AUTOSAR XML (schema 00044)
package /E40_Platform_System_SystemPackage/Components
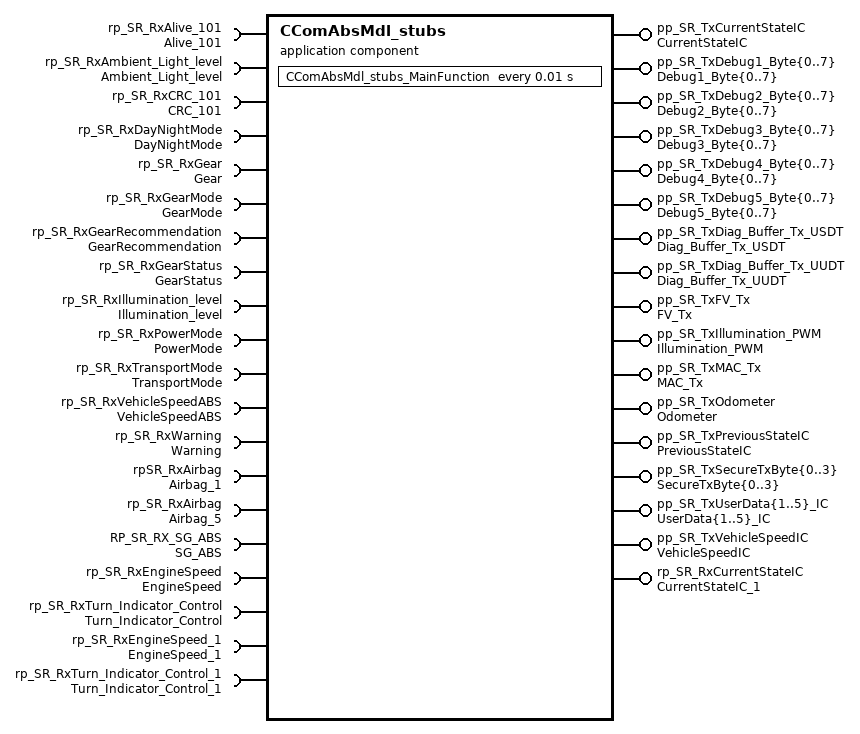
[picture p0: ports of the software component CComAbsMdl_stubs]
  application sw component type CComAbsMdl_stubs
    13 x require port:
      rp_SR_RxAlive_101: nonqueued-receiver-com-spec{data-element=Alive_101, init-value=0}, required-interface=Alive_101
      rp_SR_RxAmbient_Light_level: nonqueued-receiver-com-spec{data-element=Ambient_Light_level, init-value=0}, required-interface=Ambient_Light_level
      rp_SR_RxCRC_101: nonqueued-receiver-com-spec{data-element=CRC_101, init-value=0}, required-interface=CRC_101
      rp_SR_RxDayNightMode: nonqueued-receiver-com-spec{data-element=DayNightMode, init-value=0}, required-interface=DayNightMode
      rp_SR_RxGear: nonqueued-receiver-com-spec{data-element=Gear, init-value=0}, required-interface=Gear
      rp_SR_RxGearMode: nonqueued-receiver-com-spec{data-element=GearMode, init-value=0}, required-interface=GearMode
      rp_SR_RxGearRecommendation: nonqueued-receiver-com-spec{data-element=GearRecommendation, init-value=0}, required-interface=GearRecommendation
      rp_SR_RxGearStatus: nonqueued-receiver-com-spec{data-element=GearStatus, init-value=0}, required-interface=GearStatus
      rp_SR_RxIllumination_level: nonqueued-receiver-com-spec{data-element=Illumination_level, init-value=0}, required-interface=Illumination_level
      rp_SR_RxPowerMode: nonqueued-receiver-com-spec{data-element=PowerMode, init-value=0}, required-interface=PowerMode
      rp_SR_RxTransportMode: nonqueued-receiver-com-spec{data-element=TransportMode, init-value=0}, required-interface=TransportMode
      rp_SR_RxVehicleSpeedABS: nonqueued-receiver-com-spec{data-element=VehicleSpeedABS, init-value=0}, required-interface=VehicleSpeedABS
      rp_SR_RxWarning: nonqueued-receiver-com-spec{data-element=Warning, init-value=0}, required-interface=Warning
    58 x provide port:
      pp_SR_TxCurrentStateIC: nonqueued-sender-com-spec{data-element=CurrentStateIC, init-value=0}, provided-interface=CurrentStateIC
      pp_SR_TxDebug1_Byte{0..7}: nonqueued-sender-com-spec{data-element=Debug1_Byte{0..7}, init-value=0}, provided-interface=Debug1_Byte{0..7}
      pp_SR_TxDebug2_Byte{0..7}: nonqueued-sender-com-spec{data-element=Debug2_Byte{0..7}, init-value=0}, provided-interface=Debug2_Byte{0..7}
      pp_SR_TxDebug3_Byte{0..7}: nonqueued-sender-com-spec{data-element=Debug3_Byte{0..7}, init-value=0}, provided-interface=Debug3_Byte{0..7}
      pp_SR_TxDebug4_Byte{0..7}: nonqueued-sender-com-spec{data-element=Debug4_Byte{0..7}, init-value=0}, provided-interface=Debug4_Byte{0..7}
      pp_SR_TxDebug5_Byte{0..7}: nonqueued-sender-com-spec{data-element=Debug5_Byte{0..7}, init-value=0}, provided-interface=Debug5_Byte{0..7}
      pp_SR_TxDiag_Buffer_Tx_USDT: nonqueued-sender-com-spec{data-element=Diag_Buffer_Tx_USDT, init-value=8 x 0}, provided-interface=Diag_Buffer_Tx_USDT
      pp_SR_TxDiag_Buffer_Tx_UUDT: nonqueued-sender-com-spec{data-element=Diag_Buffer_Tx_UUDT, init-value=8 x 0}, provided-interface=Diag_Buffer_Tx_UUDT
      pp_SR_TxFV_Tx: nonqueued-sender-com-spec{data-element=FV_Tx, init-value=0}, provided-interface=FV_Tx
      pp_SR_TxIllumination_PWM: nonqueued-sender-com-spec{data-element=Illumination_PWM, init-value=0}, provided-interface=Illumination_PWM
      pp_SR_TxMAC_Tx: nonqueued-sender-com-spec{data-element=MAC_Tx, init-value=0}, provided-interface=MAC_Tx
      pp_SR_TxOdometer: nonqueued-sender-com-spec{data-element=Odometer, init-value=0}, provided-interface=Odometer
      pp_SR_TxPreviousStateIC: nonqueued-sender-com-spec{data-element=PreviousStateIC, init-value=0}, provided-interface=PreviousStateIC
      pp_SR_TxSecureTxByte{0..3}: nonqueued-sender-com-spec{data-element=SecureTxByte{0..3}, init-value=0}, provided-interface=SecureTxByte{0..3}
      pp_SR_TxUserData{1..5}_IC: nonqueued-sender-com-spec{data-element=UserData{1..5}_IC, init-value=0}, provided-interface=UserData{1..5}_IC
      pp_SR_TxVehicleSpeedIC: nonqueued-sender-com-spec{data-element=VehicleSpeedIC, init-value=0}, provided-interface=VehicleSpeedIC
    require port rpSR_RxAirbag: nonqueued-receiver-com-spec{data-element=Airbag, init-value=0}, required-interface=Airbag_1
    require port rp_SR_RxAirbag: nonqueued-receiver-com-spec{data-element=Airbag, init-value=0}, required-interface=Airbag_5
    require port RP_SR_RX_SG_ABS: nonqueued-receiver-com-spec{data-element=RP_SR_TX_SG_ABS, uses-end-to-end-protection=true, enable-update=true, filter=data-filter-type=ALWAYS, init-value=fields=[Airbag:0, Alive_101:0, CRC_101:0, VehicleSpeedABS:0]}, required-interface=SG_ABS
    provide port rp_SR_RxCurrentStateIC: nonqueued-sender-com-spec{data-element=CurrentStateIC, init-value=0}, provided-interface=CurrentStateIC_1
    4 x require port:
      rp_SR_RxEngineSpeed: nonqueued-receiver-com-spec{data-element=EngineSpeed, init-value=0}, required-interface=EngineSpeed
      rp_SR_RxTurn_Indicator_Control: nonqueued-receiver-com-spec{data-element=Turn_Indicator_Control, init-value=0}, required-interface=Turn_Indicator_Control
      rp_SR_RxEngineSpeed_1: nonqueued-receiver-com-spec{data-element=EngineSpeed, init-value=0}, required-interface=EngineSpeed_1
      rp_SR_RxTurn_Indicator_Control_1: nonqueued-receiver-com-spec{data-element=Turn_Indicator_Control, init-value=0}, required-interface=Turn_Indicator_Control_1
    behavior CComAbsMdl_stubs_InternalBehavior
      timing event TMT_CComAbsMdl_stubs_MainFunction: start-on-event=CComAbsMdl_stubs_MainFunction, period=0.01
      runnable CComAbsMdl_stubs_MainFunction
        data-receive-point-by-arguments:
          16 x access:
            REC_rp_SR_RxAlive_101_Alive_101: accessed-variable=rp_SR_RxAlive_101.Alive_101
            REC_rp_SR_RxAmbient_Light_level_Ambient_Light_level: accessed-variable=rp_SR_RxAmbient_Light_level.Ambient_Light_level
            REC_rp_SR_RxCRC_101_CRC_101: accessed-variable=rp_SR_RxCRC_101.CRC_101
            REC_rp_SR_RxDayNightMode_DayNightMode: accessed-variable=rp_SR_RxDayNightMode.DayNightMode
            REC_rp_SR_RxGear_Gear: accessed-variable=rp_SR_RxGear.Gear
            REC_rp_SR_RxGearMode_GearMode: accessed-variable=rp_SR_RxGearMode.GearMode
            REC_rp_SR_RxGearRecommendation_GearRecommendation: accessed-variable=rp_SR_RxGearRecommendation.GearRecommendation
            REC_rp_SR_RxGearStatus_GearStatus: accessed-variable=rp_SR_RxGearStatus.GearStatus
            REC_rp_SR_RxIllumination_level_Illumination_level: accessed-variable=rp_SR_RxIllumination_level.Illumination_level
            REC_rp_SR_RxPowerMode_PowerMode: accessed-variable=rp_SR_RxPowerMode.PowerMode
            REC_rp_SR_RxTransportMode_TransportMode: accessed-variable=rp_SR_RxTransportMode.TransportMode
            REC_rp_SR_RxVehicleSpeedABS_VehicleSpeedABS: accessed-variable=rp_SR_RxVehicleSpeedABS.VehicleSpeedABS
            REC_rp_SR_RxWarning_Warning: accessed-variable=rp_SR_RxWarning.Warning
            REC_RP_SR_RX_SG_ABS_RP_SR_TX_SG_ABS: accessed-variable=RP_SR_RX_SG_ABS.RP_SR_TX_SG_ABS
            REC_rp_SR_RxEngineSpeed_EngineSpeed: accessed-variable=rp_SR_RxEngineSpeed.EngineSpeed
            REC_rp_SR_RxTurn_Indicator_Control_Turn_Indicator_Control: accessed-variable=rp_SR_RxTurn_Indicator_Control.Turn_Indicator_Control
        data-send-points:
          58 x access:
            SEND_pp_SR_TxCurrentStateIC_CurrentStateIC: accessed-variable=pp_SR_TxCurrentStateIC.CurrentStateIC
            SEND_pp_SR_TxDebug1_Byte{0..7}_Debug1_Byte{0..7}: accessed-variable=pp_SR_TxDebug1_Byte{0..7}.Debug1_Byte{0..7}
            SEND_pp_SR_TxDebug2_Byte{0..7}_Debug2_Byte{0..7}: accessed-variable=pp_SR_TxDebug2_Byte{0..7}.Debug2_Byte{0..7}
            SEND_pp_SR_TxDebug3_Byte{0..7}_Debug3_Byte{0..7}: accessed-variable=pp_SR_TxDebug3_Byte{0..7}.Debug3_Byte{0..7}
            SEND_pp_SR_TxDebug4_Byte{0..7}_Debug4_Byte{0..7}: accessed-variable=pp_SR_TxDebug4_Byte{0..7}.Debug4_Byte{0..7}
            SEND_pp_SR_TxDebug5_Byte{0..7}_Debug5_Byte{0..7}: accessed-variable=pp_SR_TxDebug5_Byte{0..7}.Debug5_Byte{0..7}
            SEND_pp_SR_TxDiag_Buffer_Tx_USDT_Diag_Buffer_Tx_USDT: accessed-variable=pp_SR_TxDiag_Buffer_Tx_USDT.Diag_Buffer_Tx_USDT
            SEND_pp_SR_TxDiag_Buffer_Tx_UUDT_Diag_Buffer_Tx_UUDT: accessed-variable=pp_SR_TxDiag_Buffer_Tx_UUDT.Diag_Buffer_Tx_UUDT
            SEND_pp_SR_TxFV_Tx_FV_Tx: accessed-variable=pp_SR_TxFV_Tx.FV_Tx
            SEND_pp_SR_TxIllumination_PWM_Illumination_PWM: accessed-variable=pp_SR_TxIllumination_PWM.Illumination_PWM
            SEND_pp_SR_TxMAC_Tx_MAC_Tx: accessed-variable=pp_SR_TxMAC_Tx.MAC_Tx
            SEND_pp_SR_TxOdometer_Odometer: accessed-variable=pp_SR_TxOdometer.Odometer
            SEND_pp_SR_TxPreviousStateIC_PreviousStateIC: accessed-variable=pp_SR_TxPreviousStateIC.PreviousStateIC
            SEND_pp_SR_TxSecureTxByte{0..3}_SecureTxByte{0..3}: accessed-variable=pp_SR_TxSecureTxByte{0..3}.SecureTxByte{0..3}
            SEND_pp_SR_TxUserData{1..5}_IC_UserData{1..5}_IC: accessed-variable=pp_SR_TxUserData{1..5}_IC.UserData{1..5}_IC
            SEND_pp_SR_TxVehicleSpeedIC_VehicleSpeedIC: accessed-variable=pp_SR_TxVehicleSpeedIC.VehicleSpeedIC
  swc implementation CComAbsMdl_stubs_Implementation: behavior=CComAbsMdl_stubs_InternalBehavior
